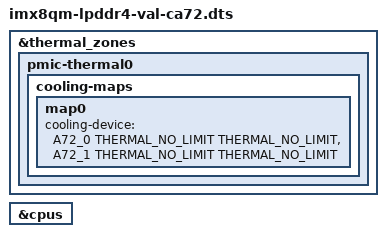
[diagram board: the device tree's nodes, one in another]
// SPDX-License-Identifier: GPL-2.0+
/*
 * Copyright 2019 NXP
 */

/dts-v1/;

#include "imx8qm-lpddr4-val.dts"

&thermal_zones {
	/delete-node/ cpu-thermal0;

	pmic-thermal0 {
		cooling-maps {
			map0 {
				cooling-device =
				<&A72_0 THERMAL_NO_LIMIT THERMAL_NO_LIMIT>,
				<&A72_1 THERMAL_NO_LIMIT THERMAL_NO_LIMIT>;
			};
		};
	};
};

&cpus {
	/delete-node/ cpu-map;
	/delete-node/ cpu@0;
	/delete-node/ cpu@1;
	/delete-node/ cpu@2;
	/delete-node/ cpu@3;
};
